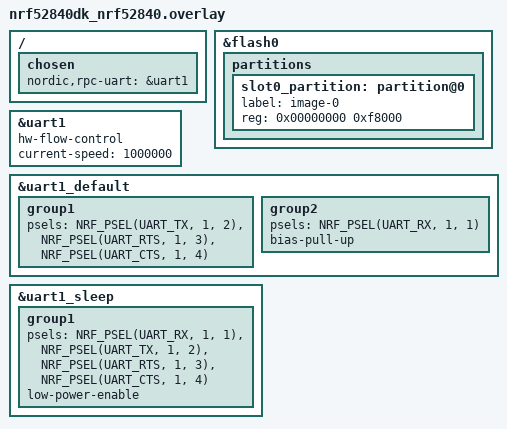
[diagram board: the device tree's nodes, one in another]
/* Copyright (c) 2024 Nordic Semiconductor ASA
 *
 * SPDX-License-Identifier: LicenseRef-Nordic-5-Clause
 */

 / {
	chosen {
		nordic,rpc-uart = &uart1;
	};
};

/delete-node/ &boot_partition;
/delete-node/ &slot0_partition;
/delete-node/ &slot1_partition;

&flash0 {
	partitions {
		slot0_partition: partition@0  {
			label = "image-0";
			reg = <0x00000000 0xf8000>;
		};
	};
};

&uart1 {
	status = "okay";
	hw-flow-control;
	current-speed = <1000000>;
};

&uart1_default {
	group1 {
		psels = <NRF_PSEL(UART_TX, 1, 2)>,
			<NRF_PSEL(UART_RTS, 1, 3)>,
			<NRF_PSEL(UART_CTS, 1, 4)>;
	};
	group2 {
		psels = <NRF_PSEL(UART_RX, 1, 1)>;
		bias-pull-up;
	};
};

&uart1_sleep {
	group1 {
		psels = <NRF_PSEL(UART_RX, 1, 1)>,
			<NRF_PSEL(UART_TX, 1, 2)>,
			<NRF_PSEL(UART_RTS, 1, 3)>,
			<NRF_PSEL(UART_CTS, 1, 4)>;
		low-power-enable;
	};
};
